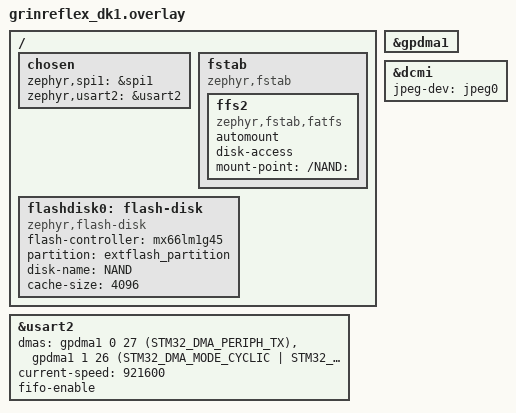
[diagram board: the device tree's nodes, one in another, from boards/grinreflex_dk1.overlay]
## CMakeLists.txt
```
#-------------------------------------------------------------------------------
# Zephyr Example Application
#
# Copyright (c) 2021 Nordic Semiconductor ASA
# SPDX-License-Identifier: Apache-2.0

cmake_minimum_required(VERSION 3.13.1)

set(EXTRA_CONF_FILE
    ${CMAKE_CURRENT_SOURCE_DIR}/lvgl.conf;
)

if (CONFIG_VARIANT_RELEASE)
set(DTC_OVERLAY_FILE ${DTC_OVERLAY_FILE};${CMAKE_CURRENT_SOURCE_DIR}/overlays/release.overlay CACHE STRING "" FORCE)
endif()

find_package(Zephyr REQUIRED HINTS $ENV{ZEPHYR_BASE})

project(gf_dkx)

target_include_directories(app PRIVATE
    src
)

target_sources(app PRIVATE
    src/main.c
)

include(${ZEPHYR_BASE}/samples/subsys/usb/common/common.cmake)

if (CONFIG_OPENCV_LIB)
    if (CONFIG_VARIAND_FACE_DETECT_ONLY)
        target_sources(app PRIVATE
            src/opencv_fd_only_app.cpp
        )
    else()
        target_sources(app PRIVATE
            src/opencv_fd_app.cpp
        )
    endif()
else()
    target_sources(app PRIVATE
        src/lvgl_video_app.cpp
    )
endif()

execute_process(
    COMMAND git describe --always --dirty
    OUTPUT_VARIABLE GIT_REVISION
)

string(REGEX REPLACE "\n$" "" GIT_REVISION "${GIT_REVISION}")

configure_file(
    src/version.h.in
    src/version.h
    @ONLY
)

target_include_directories(app PRIVATE "${CMAKE_CURRENT_BINARY_DIR}/src")
```

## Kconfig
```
# Copyright (c) 2021 Nordic Semiconductor ASA
# SPDX-License-Identifier: Apache-2.0
#
# This file is the application Kconfig entry point. All application Kconfig
# options can be defined here or included via other application Kconfig files.
# You can browse these options using the west targets menuconfig (terminal) or
# guiconfig (GUI).

#menu "Zephyr"
#source "Kconfig.zephyr"
#endmenu

module = grinreflex
module-str = grinreflex

source "subsys/logging/Kconfig.template.log_config"
source "samples/subsys/usb/common/Kconfig.sample_usbd"
source "Kconfig.zephyr"

menu "MSC sample options"

choice
	prompt "Storage and file system type used by the application"
	default APP_MSC_STORAGE_NONE
	help
	  Specify the type of storage and file system.

config APP_MSC_STORAGE_FLASH_FATFS
	bool "Use FLASH disk and FAT file system"
	imply DISK_DRIVERS
    imply DISK_ACCESS
	imply FILE_SYSTEM
	imply FAT_FILESYSTEM_ELM
    imply FILE_SYSTEM_MKFS
    imply FS_FATFS_FSTAB_AUTOMOUNT

config APP_MSC_STORAGE_NONE
    bool "Use nothing"

endchoice

config MASS_STORAGE_DISK_NAME
	default "NAND" if DISK_DRIVER_FLASH

if DISK_DRIVER_FLASH

config FLASH_MAP
	default y

config FLASH_PAGE_LAYOUT
	default y

config FLASH_LOG_LEVEL
	default 3

endif # DISK_DRIVER_FLASH

config VARIANT_RELEASE
	bool "Use release variant, strip everything that is unnecessary"
	default n
	depends on BOARD_GRINREFLEX_DK2

config VARIAND_FACE_DETECT_ONLY
	bool "Build only face detector"
	default n

endmenu
```

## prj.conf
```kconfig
# Copyright (c) 2021 Nordic Semiconductor ASA
# SPDX-License-Identifier: Apache-2.0
#
# This is a Kconfig fragment which can be used to enable debug-related options
# in the application. See the README for more details.

CONFIG_CPP=y
CONFIG_STD_CPP20=y
CONFIG_CPP_EXCEPTIONS=y
CONFIG_CPP_RTTI=y

CONFIG_MAIN_STACK_SIZE=65536

# Ensure logs/printk come out before the crash
CONFIG_PRINTK=y
CONFIG_LOG=y
CONFIG_LOG_PRINTK=y
CONFIG_LOG_DEFAULT_LEVEL=3
CONFIG_LOG_MODE_MINIMAL=y
CONFIG_LOG_MODE_DEFERRED=n     # immediate logs
#CONFIG_LOG_MODE_IMMEDIATE=y

CONFIG_SHELL=y

CONFIG_INPUT=y

CONFIG_REQUIRES_FULL_LIBC=y
CONFIG_GLIBCXX_LIBCPP=y

CONFIG_NEWLIB_LIBC=y
CONFIG_PICOLIBC=n

CONFIG_COMMON_LIBC_MALLOC=y
CONFIG_HEAP_MEM_POOL_SIZE=8192
#CONFIG_COMMON_LIBC_MALLOC_ARENA_SIZE=2097152
CONFIG_COMMON_LIBC_MALLOC_ARENA_SIZE=1503232

CONFIG_POSIX_API=y

CONFIG_ASSERT=y
# Make asserts print file:line and message
CONFIG_ASSERT_VERBOSE=y

#CONFIG_STACK_SENTINEL=y
#CONFIG_THREAD_STACK_INFO=y
#CONFIG_INIT_STACKS=y           # fill stacks, helps detect overflow

#CONFIG_DEBUG_OPTIMIZATIONS=y
CONFIG_SPEED_OPTIMIZATIONS=y

#CONFIG_TFLITE_LIB=y
CONFIG_OPENCV_LIB=y
#CONFIG_QUIRC_LIB=y
CONFIG_NEMA=y

CONFIG_FPU=y
CONFIG_FP_SOFTABI=y

CONFIG_GPIO=y
#CONFIG_SPI=y
#CONFIG_SPI_LOG_LEVEL_DBG=y

CONFIG_DMA=y
CONFIG_DMA_LOG_LEVEL_INF=y

CONFIG_SERIAL=y
CONFIG_RING_BUFFER=y
#CONFIG_UART_LOG_LEVEL_DBG=y

CONFIG_UART_ASYNC_API=y
CONFIG_UART_INTERRUPT_DRIVEN=y

CONFIG_STM32_JPEG=y

#CONFIG_DISPLAY_LOG_LEVEL_DBG=y

#CONFIG_HW_STACK_PROTECTION=y

# Better symbols for gdb
#CONFIG_DEBUG_INFO=y
# (Optional) minimal optimizations for nicer backtraces
# CONFIG_NO_OPTIMIZATIONS=y

# Richer fault dump on ARM (registers, etc.)
CONFIG_FAULT_DUMP=2

CONFIG_VIDEO_SHELL=y

CONFIG_STM32_JPEG_RGB_FORMAT=3
CONFIG_GRINREFLEX_JPEG_VIDEO=y
CONFIG_GRINREFLEX_JPEG_VIDEO_QUALITY=20
CONFIG_GRINREFLEX_VIDEO_WIDTH=640
CONFIG_GRINREFLEX_VIDEO_HEIGHT=480

#CONFIG_VIDEO_LOG_LEVEL_DBG=y
CONFIG_VIDEO_LOG_LEVEL_WRN=y
CONFIG_VIDEO_LOG_LEVEL_ERR=y

#CONFIG_VIDEO_BUFFER_POOL_SZ_MAX=76800
CONFIG_VIDEO_BUFFER_POOL_SZ_MAX=153600
```

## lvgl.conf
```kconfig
CONFIG_LV_Z_MEM_POOL_SIZE=16384
CONFIG_LV_Z_SHELL=n

CONFIG_LVGL=y
CONFIG_LV_USE_LOG=n
CONFIG_LV_USE_LABEL=n
CONFIG_LV_USE_ARC=y
CONFIG_LV_USE_IMAGE=y
#CONFIG_LV_USE_MONKEY=y
CONFIG_LV_FONT_MONTSERRAT_14=y
#CONFIG_LV_Z_POINTER_INPUT=y

CONFIG_LV_CACHE_DEF_SIZE=4096
CONFIG_LV_IMAGE_HEADER_CACHE_DEF_CNT=1
#CONFIG_LV_USE_TJPGD=y
#CONFIG_LV_USE_FS_MEMFS=y
#CONFIG_LV_USE_FS=y
CONFIG_LV_USE_BUILTIN_MALLOC=n

#CONFIG_LV_USE_PERF_MONITOR=y
#CONFIG_LV_USE_DROPDOWN=y
#CONFIG_LV_USE_SYSMON=y
```

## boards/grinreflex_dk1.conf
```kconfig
#CONFIG_USB_DEVICE_STACK_NEXT=y
#CONFIG_USBD_MSC_CLASS=y
#CONFIG_USBD_MSC_LUNS_PER_INSTANCE=3
#CONFIG_USBD_LOG_LEVEL_WRN=y
#CONFIG_UDC_DRIVER_LOG_LEVEL_WRN=y

#CONFIG_SAMPLE_USBD_PID=0x0008
#CONFIG_SAMPLE_USBD_PRODUCT="USBD MSC sample"

#CONFIG_FILE_SYSTEM_SHELL=y

#CONFIG_USB_DEVICE_INITIALIZE_AT_BOOT=n
```

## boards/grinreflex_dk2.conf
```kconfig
CONFIG_FAT_FILESYSTEM_ELM=n
CONFIG_POSIX_FILE_SYSTEM=n

CONFIG_VIDEO_SHELL=y
```

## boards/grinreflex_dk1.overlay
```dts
/*
 * Copyright (c) 2024, Eve Redero
 *
 * SPDX-License-Identifier: Apache-2.0
 */

#include <zephyr/dt-bindings/input/input-event-codes.h>
#include <zephyr/dt-bindings/lvgl/lvgl.h>

/ {
	chosen: chosen {
		zephyr,spi1 = &spi1;
		zephyr,usart2 = &usart2;
	};

	fstab {
		compatible = "zephyr,fstab";

        ffs2: ffs2 {
			compatible = "zephyr,fstab,fatfs";
			automount;
			disk-access;
			mount-point = "/NAND:";
		};
	};

    flashdisk0: flash-disk {
        compatible = "zephyr,flash-disk";
        flash-controller = <&mx66lm1g45>;
        partition = <&extflash_partition>;
        disk-name = "NAND";
        cache-size = <4096>;
    };
};

&usart2 {
	dmas = <&gpdma1 0 27 (STM32_DMA_PERIPH_TX)
			&gpdma1 1 26 (STM32_DMA_MODE_CYCLIC | STM32_DMA_PERIPH_RX | STM32_DMA_MEM_8BITS)>;
	dma-names = "tx", "rx";
	current-speed = <921600>;
	fifo-enable;
};

&gpdma1 {
	status = "okay";
};

&dcmi {
	jpeg-dev = <&jpeg0>;
};
```

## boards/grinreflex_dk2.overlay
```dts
/*
 * Copyright (c) 2024, Eve Redero
 *
 * SPDX-License-Identifier: Apache-2.0
 */

#include <zephyr/dt-bindings/input/input-event-codes.h>
#include <zephyr/dt-bindings/lvgl/lvgl.h>

/ {
	chosen: chosen {
		zephyr,spi1 = &spi1;
	};
};

&gpdma1 {
	status = "okay";
};

&dcmi {
	jpeg-dev = <&jpeg0>;
};
```

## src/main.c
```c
/*
 * Copyright (c) 2024 Charles Dias <charlesdias.cd@outlook.com>
 *
 * SPDX-License-Identifier: Apache-2.0
 */

#include <lvgl.h>
#include <zephyr/device.h>
#include <zephyr/drivers/display.h>
#include <zephyr/drivers/video-controls.h>
#include <zephyr/drivers/video.h>
#include <zephyr/kernel.h>
#include <zephyr/logging/log.h>

#define CONFIG_VIDEO_WIDTH 160
#define CONFIG_VIDEO_HEIGHT 120

#include "grinreflex.h"

LOG_MODULE_REGISTER(main, CONFIG_LOG_DEFAULT_LEVEL);

#if !DT_HAS_CHOSEN(zephyr_camera)
#error No camera chosen in devicetree. Missing "--shield" or "--snippet video-sw-generator" flag?
#endif

#if !DT_HAS_CHOSEN(zephyr_display)
#error No display chosen in devicetree. Missing "--shield" flag?
#endif

int main(void) {
  init();

  while (1) {
    loop();
  }
}
```

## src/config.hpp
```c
#pragma once

#if !defined(CONFIG_GRINREFLEX_JPEG_VIDEO)
#error "Not supported yet"
#endif

#if defined(CONFIG_STM32_JPEG_RGB_FORMAT)
#if CONFIG_STM32_JPEG_RGB_FORMAT == 0
#define FULL_FRAME_COLOR_FORMAT LV_COLOR_FORMAT_ARGB8888
#elif CONFIG_STM32_JPEG_RGB_FORMAT == 1
#define FULL_FRAME_COLOR_FORMAT LV_COLOR_FORMAT_RGB888
#elif CONFIG_STM32_JPEG_RGB_FORMAT == 2
#define FULL_FRAME_COLOR_FORMAT LV_COLOR_FORMAT_RGB565
#elif CONFIG_STM32_JPEG_RGB_FORMAT == 3
#define FULL_FRAME_COLOR_FORMAT LV_COLOR_FORMAT_L8
#else
#error "CONFIG_STM32_JPEG_RGB_FORMAT is not supported"
#endif

#else
#define FULL_FRAME_COLOR_FORMAT LV_COLOR_FORMAT_RGB888
#endif /* defined(CONFIG_STM32_JPEG_RGB_FORMAT) */

#define FULL_FRAME_WIDTH CONFIG_GRINREFLEX_VIDEO_WIDTH
#define FULL_FRAME_HEIGHT CONFIG_GRINREFLEX_VIDEO_HEIGHT

#define ROI_FRAME_WIDTH 320
#define ROI_FRAME_HEIGHT 240

#define THUMBNAIL_FRAME_WIDTH 90
#define THUMBNAIL_FRAME_HEIGHT 90

#define INPUT_PREPROCESS_OPENCV (0)
#define FULL_FRAME_FLIP_Y (0)
```

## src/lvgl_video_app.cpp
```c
#include <iostream>
#include <vector>

#if defined(CONFIG_OPENCV_LIB)
#include "cascades.h"
#include "opencv2/opencv.hpp"
#include "opencv_utils.hpp"
#endif

#include <lvgl.h>
#include <lvgl_input_device.h>
#include <stdio.h>
#include <string.h>
#include <zephyr/device.h>
#include <zephyr/devicetree.h>
#include <zephyr/drivers/display.h>
#include <zephyr/drivers/gpio.h>
#include <zephyr/kernel.h>

#include <stdio.h>

#define LOG_LEVEL CONFIG_LOG_DEFAULT_LEVEL
#include <zephyr/logging/log.h>
LOG_MODULE_REGISTER(grinreflex_app);

#include <app/drivers/jpeg.h>

#include "config.hpp"
#include "gf/lvgl_utils.hpp"
#include "gf/utils.hpp"
#include "gf/video.hpp"
#include "grinreflex.h"

static const struct device *video_dev = DEVICE_DT_GET(DT_CHOSEN(zephyr_camera));
static const struct device *display_dev =
    DEVICE_DT_GET(DT_CHOSEN(zephyr_display));
const struct device *jpeg_dev = DEVICE_DT_GET(DT_CHOSEN(zephyr_jpeg));

static uint8_t
    fullFrameBuffer[FULL_FRAME_WIDTH * FULL_FRAME_HEIGHT *
                    LV_COLOR_FORMAT_GET_SIZE(FULL_FRAME_COLOR_FORMAT)];
static uint8_t roiFrameBuffer[ROI_FRAME_WIDTH * ROI_FRAME_HEIGHT *
                              LV_COLOR_FORMAT_GET_SIZE(LV_COLOR_FORMAT_L8)];
static uint8_t
    thumbnailFrameBuffer[THUMBNAIL_FRAME_WIDTH * THUMBNAIL_FRAME_HEIGHT *
                         LV_COLOR_FORMAT_GET_SIZE(LV_COLOR_FORMAT_L8)];

static lv_obj_t *screen_canvas;
static lv_obj_t *dummy_canvas;

int init() {
  if (!device_is_ready(display_dev)) {
    LOG_ERR("Display device not ready, aborting test");
    return -ENODEV;
  }

  if (!device_is_ready(video_dev)) {
    LOG_ERR("Video device not ready, aborting test");
    return -ENODEV;
  }

  if (!device_is_ready(jpeg_dev)) {
    printf("%s JPEG device not ready", jpeg_dev->name);
    return -ENODEV;
  }

  Video::setup();

  dummy_canvas = lv_canvas_create(NULL);
  screen_canvas = lv_canvas_create(lv_screen_active());
  lv_canvas_fill_bg(screen_canvas, lv_color_hex3(0xccc), LV_OPA_COVER);
  lv_obj_center(screen_canvas);

  display_blanking_off(display_dev);

  return 0;
}

int loop() {

  struct video_buffer vbuf {};
  struct video_buffer *vbuf_ptr = &vbuf;
  struct jpeg_out_prop jpeg_prop;

  vbuf_ptr->type = VIDEO_BUF_TYPE_OUTPUT;

  int err = video_dequeue(video_dev, &vbuf_ptr, K_FOREVER);
  if (err) {
    LOG_ERR("Unable to dequeue video buf");
    return 0;
  }

  // jpeg_hw_decode(jpeg_dev, (uint8_t *)vbuf_ptr->buffer, vbuf_ptr->bytesused,
  // jpeg_frame_buffer);

  jpeg_hw_poll(jpeg_dev, 0, &jpeg_prop);

  // printf("JPEG done w = %d, h = %d, color = %d chroma = %d\n",
  // jpeg_prop.width,
  //         jpeg_prop.height, jpeg_prop.color_space, jpeg_prop.chroma);

  jpeg_color_convert_helper(jpeg_dev, &jpeg_prop, vbuf_ptr->buffer,
                            fullFrameBuffer);

  cropFullFrameToRoi(dummy_canvas, fullFrameBuffer, roiFrameBuffer);
  fitRoiFrameToThumbnail(screen_canvas, roiFrameBuffer, thumbnailFrameBuffer);
  lv_task_handler();

  err = video_enqueue(video_dev, vbuf_ptr);
  if (err) {
    LOG_ERR("Unable to requeue video buf");
  }

  k_msleep(50);

  return 0;
}
```

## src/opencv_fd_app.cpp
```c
#include <iostream>
#include <vector>

#if defined(CONFIG_OPENCV_LIB)
#include "cascades.h"
#include "gf/opencv_utils.hpp"
#include "opencv2/opencv.hpp"
#endif

#include <lvgl.h>
#include <lvgl_input_device.h>
#include <stdio.h>
#include <string.h>
#include <zephyr/device.h>
#include <zephyr/devicetree.h>
#include <zephyr/drivers/display.h>
#include <zephyr/drivers/gpio.h>
#include <zephyr/kernel.h>

#include <stdio.h>

#define LOG_LEVEL CONFIG_LOG_DEFAULT_LEVEL
#include <zephyr/logging/log.h>
LOG_MODULE_REGISTER(grinreflex_app);

#include "gf/lvgl_utils.hpp"
#include "gf/video.hpp"

#include <app/drivers/jpeg.h>

#include "config.hpp"
#include "gf/utils.hpp"
#include "grinreflex.h"

using namespace gf_cv;

static const struct device *video_dev = DEVICE_DT_GET(DT_CHOSEN(zephyr_camera));
static const struct device *display_dev =
    DEVICE_DT_GET(DT_CHOSEN(zephyr_display));
const struct device *jpeg_dev = DEVICE_DT_GET(DT_CHOSEN(zephyr_jpeg));
#if DT_NODE_EXISTS(DT_ALIAS(led0))
static const struct gpio_dt_spec led = GPIO_DT_SPEC_GET(DT_ALIAS(led0), gpios);
#endif

static uint8_t
    fullFrameBuffer[FULL_FRAME_WIDTH * FULL_FRAME_HEIGHT *
                    LV_COLOR_FORMAT_GET_SIZE(FULL_FRAME_COLOR_FORMAT)];
static uint8_t roiFrameBuffer[ROI_FRAME_WIDTH * ROI_FRAME_HEIGHT *
                              LV_COLOR_FORMAT_GET_SIZE(LV_COLOR_FORMAT_L8)];
static uint8_t
    thumbnailFrameBuffer[THUMBNAIL_FRAME_WIDTH * THUMBNAIL_FRAME_HEIGHT *
                         LV_COLOR_FORMAT_GET_SIZE(LV_COLOR_FORMAT_L8)];

static lv_obj_t *screen_canvas;
static lv_obj_t *dummy_canvas;
static lv_obj_t *screen;

static lv_obj_t *ROIRectFace;
static lv_obj_t *ROIRectSmile;
static cv::CascadeClassifier faceCascade;
static cv::CascadeClassifier smileCascade;

int init() {
  if (!device_is_ready(display_dev)) {
    LOG_ERR("Display device not ready, aborting test");
    return -ENODEV;
  }

  if (!device_is_ready(video_dev)) {
    LOG_ERR("Video device not ready, aborting test");
    return -ENODEV;
  }

  if (!device_is_ready(jpeg_dev)) {
    printf("%s JPEG device not ready", jpeg_dev->name);
    return -ENODEV;
  }

#if DT_NODE_EXISTS(DT_ALIAS(led0))
  if (!gpio_is_ready_dt(&led)) {
    return -ENODEV;
  }

  if (gpio_pin_configure_dt(&led, GPIO_OUTPUT_ACTIVE) < 0) {
    return -ENODEV;
  }
#endif

  cv::setNumThreads(1);
  cv::setUseOptimized(false);

  if (false ==
      loadCascade(faceCascade, cascade_face_data(), cascade_face_len())) {
    return -3;
  }

  if (false ==
      loadCascade(smileCascade, cascade_smile_data(), cascade_smile_len())) {
    return -3;
  }

  Video::setup();

  dummy_canvas = lv_canvas_create(NULL);
  screen_canvas = lv_canvas_create(lv_screen_active());
  lv_canvas_fill_bg(screen_canvas, lv_color_hex3(0xccc), LV_OPA_COVER);
  lv_obj_center(screen_canvas);

  display_blanking_off(display_dev);

  screen = lv_img_create(lv_scr_act());

  ROIRectFace =
      allocLvROIRect(lv_scr_act(), 4, lv_palette_main(LV_PALETTE_GREEN));
  ROIRectSmile =
      allocLvROIRect(lv_scr_act(), 4, lv_palette_main(LV_PALETTE_RED));

  return 0;
}

int loop() {
  struct video_buffer vbuf {};
  struct video_buffer *vbuf_ptr = &vbuf;
  struct jpeg_out_prop jpeg_prop;

  vbuf_ptr->type = VIDEO_BUF_TYPE_OUTPUT;

  int err = video_dequeue(video_dev, &vbuf_ptr, K_FOREVER);
  if (err) {
    LOG_ERR("Unable to dequeue video buf");
    return 0;
  }

  // jpeg_hw_decode(jpeg_dev, (uint8_t *)vbuf_ptr->buffer, vbuf_ptr->bytesused,
  // jpeg_frame_buffer);

  jpeg_hw_poll(jpeg_dev, 0, &jpeg_prop);

  // printf("JPEG done w = %d, h = %d, color = %d chroma = %d\n",
  // jpeg_prop.width,
  //         jpeg_prop.height, jpeg_prop.color_space, jpeg_prop.chroma);

  jpeg_color_convert_helper(jpeg_dev, &jpeg_prop, vbuf_ptr->buffer,
                            fullFrameBuffer);

  cropFullFrameToRoi(dummy_canvas, fullFrameBuffer, roiFrameBuffer,
                     lvgl::Size(FULL_FRAME_WIDTH, FULL_FRAME_HEIGHT),
                     lvgl::Size(ROI_FRAME_WIDTH, ROI_FRAME_HEIGHT),
                     FULL_FRAME_COLOR_FORMAT, LV_COLOR_FORMAT_L8,
                     FULL_FRAME_FLIP_Y);

  fitRoiFrameToThumbnail(
      screen_canvas, roiFrameBuffer, thumbnailFrameBuffer,
      lvgl::Size(ROI_FRAME_WIDTH, ROI_FRAME_HEIGHT),
      lvgl::Size(THUMBNAIL_FRAME_WIDTH, THUMBNAIL_FRAME_HEIGHT),
      LV_COLOR_FORMAT_L8, LV_COLOR_FORMAT_L8);
  lv_task_handler();

  // Return buffer back, we don't need it anymore, thank you
  err = video_enqueue(video_dev, vbuf_ptr);
  if (err) {
    LOG_ERR("Unable to requeue video buf");
    return 0;
  }

  cv::Mat matGraySmall(THUMBNAIL_FRAME_HEIGHT, THUMBNAIL_FRAME_WIDTH, CV_8UC1,
                       thumbnailFrameBuffer);
  cv::Mat matGrayFull(ROI_FRAME_HEIGHT, ROI_FRAME_WIDTH, CV_8UC1,
                      roiFrameBuffer);

  // This is the best configuration I could find, 64 x 30 works even better
  // But that may miss smile area
  cv::Rect faceROIMax(0, 0, 64, 40);

  auto sigmaX = Range<float>{0.75, 0.85, 0.05};
  BlurStage blurStage = BlurStage(sigmaX);

  auto _gamma = Range<float>{0.35, 0.55, 0.05};
  GammaStage gammaStage = GammaStage(_gamma);

  auto d = Range<int>{3, 3, 1};
  auto sigmaColor = Range<float>{10.0, 30.0, 10.0};
  auto sigmaSpace = Range<float>{50.0, 50.0, 1.0};
  BilateralStage bilateralStage = BilateralStage(d, sigmaColor, sigmaSpace);

  auto clipLimit = Range<float>{4.0, 4.0, 1.0};
  auto tileSize = Range<int>{4, 4, 1};
  ClaheStage claheStage = ClaheStage(clipLimit, tileSize);
  claheStage.setNextStage(&bilateralStage);
  bilateralStage.setNextStage(&gammaStage);
  gammaStage.setNextStage(nullptr);
  // blurStage.setNextStage(nullptr);

  cv::equalizeHist(matGraySmall, matGraySmall);
  auto rects = detectFaceAndSmile(faceCascade, smileCascade, matGraySmall,
                                  matGrayFull, faceROIMax, claheStage);

  cv::Rect face, smile;
  if (rects.size()) {
    lv_obj_remove_flag(ROIRectFace, LV_OBJ_FLAG_HIDDEN);

    face = rects[0];
    lv_obj_align_to(ROIRectFace, screen_canvas, LV_ALIGN_TOP_LEFT, face.x,
                    face.y);
    lv_obj_set_size(ROIRectFace, face.width, face.height);

  } else {
    lv_obj_add_flag(ROIRectFace, LV_OBJ_FLAG_HIDDEN);
  }

  if (rects.size() > 1) {
    smile = rects[1];
    if ((smile & face).area() != 0) {
      lv_obj_align_to(ROIRectSmile, screen_canvas, LV_ALIGN_TOP_LEFT, smile.x,
                      smile.y);
      lv_obj_set_size(ROIRectSmile, smile.width, smile.height);

      lv_obj_remove_flag(ROIRectSmile, LV_OBJ_FLAG_HIDDEN);
#if DT_NODE_EXISTS(DT_ALIAS(led0))
      gpio_pin_set_dt(&led, 0);
#endif
    }
  } else {
    lv_obj_add_flag(ROIRectSmile, LV_OBJ_FLAG_HIDDEN);
  }

  return 0;
}
```

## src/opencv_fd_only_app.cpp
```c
#include <iostream>
#include <vector>

#if defined(CONFIG_OPENCV_LIB)
#include "cascades.h"
#include "gf/opencv_utils.hpp"
#include "opencv2/opencv.hpp"
#endif

#include <lvgl.h>
#include <lvgl_input_device.h>
#include <stdio.h>
#include <string.h>
#include <zephyr/device.h>
#include <zephyr/devicetree.h>
#include <zephyr/drivers/display.h>
#include <zephyr/drivers/gpio.h>
#include <zephyr/kernel.h>

#include <stdio.h>

#define LOG_LEVEL CONFIG_LOG_DEFAULT_LEVEL
#include <zephyr/logging/log.h>
LOG_MODULE_REGISTER(grinreflex_app);

#include "gf/lvgl_utils.hpp"
#include "gf/video.hpp"

#include <app/drivers/jpeg.h>

#include "config.hpp"
#include "gf/utils.hpp"
#include "grinreflex.h"

using namespace gf_cv;

static const struct device *video_dev = DEVICE_DT_GET(DT_CHOSEN(zephyr_camera));

static const struct device *display_dev =
    DEVICE_DT_GET(DT_CHOSEN(zephyr_display));

const struct device *jpeg_dev = DEVICE_DT_GET(DT_CHOSEN(zephyr_jpeg));

#if DT_NODE_EXISTS(DT_ALIAS(led0))
static const struct gpio_dt_spec led = GPIO_DT_SPEC_GET(DT_ALIAS(led0), gpios);
#endif

static uint8_t
    fullFrameBuffer[FULL_FRAME_WIDTH * FULL_FRAME_HEIGHT *
                    LV_COLOR_FORMAT_GET_SIZE(FULL_FRAME_COLOR_FORMAT)];
static uint8_t roiFrameBuffer[ROI_FRAME_WIDTH * ROI_FRAME_HEIGHT *
                              LV_COLOR_FORMAT_GET_SIZE(LV_COLOR_FORMAT_L8)];
static uint8_t
    thumbnailFrameBuffer[THUMBNAIL_FRAME_WIDTH * THUMBNAIL_FRAME_HEIGHT *
                         LV_COLOR_FORMAT_GET_SIZE(LV_COLOR_FORMAT_L8)];

static lv_obj_t *screen_canvas;
static lv_obj_t *dummy_canvas;

#if INPUT_PREPROCESS_OPENCV
static lv_obj_t *lvgl_image;
#endif

static lv_obj_t *ROIRectFace;
static cv::CascadeClassifier faceCascade;

int init() {
  if (!device_is_ready(display_dev)) {
    LOG_ERR("Display device not ready, aborting test");
    return -ENODEV;
  }

  if (!device_is_ready(video_dev)) {
    LOG_ERR("Video device not ready, aborting test");
    return -ENODEV;
  }

  if (!device_is_ready(jpeg_dev)) {
    printf("%s JPEG device not ready", jpeg_dev->name);
    return -ENODEV;
  }

#if DT_NODE_EXISTS(DT_ALIAS(led0))
  if (!gpio_is_ready_dt(&led)) {
    return -ENODEV;
  }

  if (gpio_pin_configure_dt(&led, GPIO_OUTPUT_ACTIVE) < 0) {
    return -ENODEV;
  }
#endif

  cv::setNumThreads(1);
  cv::setUseOptimized(false);

  if (false ==
      loadCascade(faceCascade, cascade_face_data(), cascade_face_len())) {
    return -3;
  }

  Video::setup();

  dummy_canvas = lv_canvas_create(NULL);
  screen_canvas = lv_canvas_create(lv_screen_active());
  lv_canvas_fill_bg(screen_canvas, lv_color_hex3(0xccc), LV_OPA_COVER);
  lv_obj_center(screen_canvas);

#if INPUT_PREPROCESS_OPENCV
  lvgl_image = lv_img_create(lv_scr_act());
  lv_obj_center(lvgl_image);
#endif

  display_blanking_off(display_dev);

  ROIRectFace =
      allocLvROIRect(lv_scr_act(), 4, lv_palette_main(LV_PALETTE_GREEN));

  return 0;
}

int loop() {
  struct video_buffer vbuf {};
  struct video_buffer *vbuf_ptr = &vbuf;
  struct jpeg_out_prop jpeg_prop;

  vbuf_ptr->type = VIDEO_BUF_TYPE_OUTPUT;

  int err = video_dequeue(video_dev, &vbuf_ptr, K_FOREVER);
  if (err) {
    LOG_ERR("Unable to dequeue video buf");
    return 0;
  }

  // jpeg_hw_decode(jpeg_dev, (uint8_t *)vbuf_ptr->buffer, vbuf_ptr->bytesused,
  // jpeg_frame_buffer);

  jpeg_hw_poll(jpeg_dev, 0, &jpeg_prop);

  // printf("JPEG done w = %d, h = %d, color = %d chroma = %d\n",
  // jpeg_prop.width,
  //         jpeg_prop.height, jpeg_prop.color_space, jpeg_prop.chroma);

  jpeg_color_convert_helper(jpeg_dev, &jpeg_prop, vbuf_ptr->buffer,
                            fullFrameBuffer);

  // TODO: matGraySmall can be dynamically allocated, and freed after face
  // detection stage passed. That will free some resources for smile detection
  // phase
  cv::Mat matGraySmall(THUMBNAIL_FRAME_HEIGHT, THUMBNAIL_FRAME_WIDTH, CV_8UC1,
                       thumbnailFrameBuffer);

// TODO hide logic below into utils.cpp
// when INPUT_PREPROCESS_OPENCV==1 that doesn't allow flipping at the moment,
// so not all cameras would work
#if INPUT_PREPROCESS_OPENCV
  cv::Rect crop;
  crop.width = ROI_FRAME_WIDTH;
  crop.height = ROI_FRAME_HEIGHT;
  crop.x = (matGrayFull.cols - crop.width) / 2;
  crop.y = crop.height;
  cv::Mat matCrop = matGrayFull(crop);
  matCrop.copyTo(matGrayRoi);
  cv::resize(matGrayRoi, matGraySmall,
             cv::Size(THUMBNAIL_FRAME_WIDTH, THUMBNAIL_FRAME_HEIGHT), 0.0f,
             0.0f, cv::INTER_NEAREST);

  displayFrame(lvgl_image, thumbnailFrameBuffer,
               lvgl::Size(THUMBNAIL_FRAME_WIDTH, THUMBNAIL_FRAME_HEIGHT),
               LV_COLOR_FORMAT_L8);
#else
  cropFullFrameToRoi(dummy_canvas, fullFrameBuffer, roiFrameBuffer,
                     lvgl::Size(FULL_FRAME_WIDTH, FULL_FRAME_HEIGHT),
                     lvgl::Size(ROI_FRAME_WIDTH, ROI_FRAME_HEIGHT),
                     FULL_FRAME_COLOR_FORMAT, LV_COLOR_FORMAT_L8,
                     FULL_FRAME_FLIP_Y);

  fitRoiFrameToThumbnail(
      screen_canvas, roiFrameBuffer, thumbnailFrameBuffer,
      lvgl::Size(ROI_FRAME_WIDTH, ROI_FRAME_HEIGHT),
      lvgl::Size(THUMBNAIL_FRAME_WIDTH, THUMBNAIL_FRAME_HEIGHT),
      LV_COLOR_FORMAT_L8, LV_COLOR_FORMAT_L8);

#endif /* #if INPUT_PREPROCESS_OPENCV */
  lv_task_handler();

  // Return buffer back, we don't need it anymore, thank you
  err = video_enqueue(video_dev, vbuf_ptr);
  if (err) {
    LOG_ERR("Unable to requeue video buf");
    return 0;
  }

  cv::equalizeHist(matGraySmall, matGraySmall);
  auto rects = detectFace(faceCascade, matGraySmall);

  lv_obj_t *draw_widget = screen_canvas;
#if INPUT_PREPROCESS_OPENCV
  draw_widget = lvgl_image;
#endif

  cv::Rect face;
  if (rects.size()) {
    lv_obj_remove_flag(ROIRectFace, LV_OBJ_FLAG_HIDDEN);

    face = rects[0];
    lv_obj_align_to(ROIRectFace, draw_widget, LV_ALIGN_TOP_LEFT, face.x,
                    face.y);
    lv_obj_set_size(ROIRectFace, face.width, face.height);
#if DT_NODE_EXISTS(DT_ALIAS(led0))
    gpio_pin_set_dt(&led, 0);
#endif
  } else {
    lv_obj_add_flag(ROIRectFace, LV_OBJ_FLAG_HIDDEN);
  }

  k_msleep(1);

  return 0;
}
```
